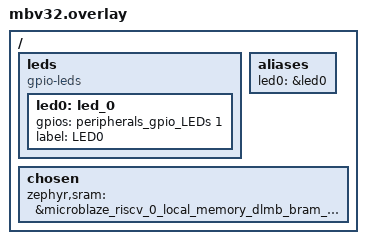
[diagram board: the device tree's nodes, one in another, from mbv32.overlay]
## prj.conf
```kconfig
CONFIG_PRINTK=y
CONFIG_CONSOLE=y
CONFIG_GPIO=y
CONFIG_MAIN_STACK_SIZE=1024

CONFIG_NO_OPTIMIZATIONS=y
```

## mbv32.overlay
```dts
#include <zephyr/dt-bindings/gpio/gpio.h>

/ {
    leds {
        compatible = "gpio-leds";

        led0: led_0 {
            gpios = <&peripherals_gpio_LEDs 1 GPIO_ACTIVE_HIGH>;
            label = "LED0";
        };
    };

    aliases {
        led0 = &led0;
    };

    chosen {
        zephyr,sram  = &microblaze_riscv_0_local_memory_dlmb_bram_if_cntlr0_memory;
    };
};
```

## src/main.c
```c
#include <zephyr/kernel.h>
#include <zephyr/sys/printk.h>


#include "led.h"

/* Thread stack */
#define STACK_SIZE 4096
#define PRIORITY 5

K_THREAD_STACK_DEFINE(led_stack, STACK_SIZE);
struct k_thread led_thread_data;



int main(void)
{
    uint32_t loops = 0;
    printk("Hello from my own Zephyr app on MicroBlaze V!\n");

    /* Create LED thread */
    k_thread_create(&led_thread_data, led_stack,
                    STACK_SIZE,
                    led_thread,
                    NULL, NULL, NULL,
                    PRIORITY, 0, K_NO_WAIT);

    while (1) {
        printk("Uptime: %lld ms\n", k_uptime_get());
        k_sleep(K_SECONDS(1));
        loops++;
    }

    return 0;
}
```

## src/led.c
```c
#include <zephyr/kernel.h>
#include <zephyr/sys/printk.h>
#include <zephyr/drivers/gpio.h>

/* Get LED from devicetree */
#define LED0_NODE DT_ALIAS(led0)

#if !DT_NODE_HAS_STATUS(LED0_NODE, okay)
#error "No LED0 alias found in device tree"
#endif

static const struct gpio_dt_spec led = GPIO_DT_SPEC_GET(LED0_NODE, gpios);



/* LED thread function */
void led_thread(void *arg1, void *arg2, void *arg3)
{
    uint32_t loops = 0;
    if (!gpio_is_ready_dt(&led)) {
        printk("LED device not ready\n");
        return;
    }

    gpio_pin_configure_dt(&led, GPIO_OUTPUT_ACTIVE);

    while (1) {
        gpio_pin_toggle_dt(&led);
        k_sleep(K_MSEC(50));
        loops++;
    }
}
```

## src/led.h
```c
#ifndef LED_H
#define LED_H

void led_thread(void *arg1, void *arg2, void *arg3);

#endif
```
